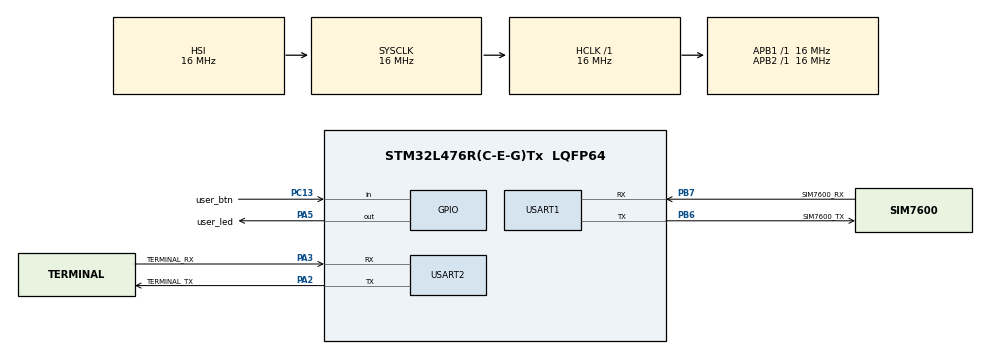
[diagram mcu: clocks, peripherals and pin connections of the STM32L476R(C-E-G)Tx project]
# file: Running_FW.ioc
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Mcu.Family=STM32L4
RCC.MSI_VALUE=4000000
RCC.PLLSourceVirtual=RCC_PLLSOURCE_HSI
PA14\ (JTCK-SWCLK).Mode=Serial_Wire
RCC.CortexFreq_Value=16000000
PC13.Signal=GPIO_Input
PB6.GPIO_Label=SIM7600_TX
PC13.GPIO_Label=user_btn
NVIC.USART2_IRQn=true\:0\:0\:false\:false\:true\:true\:true
RCC.SYSCLKSource=RCC_SYSCLKSOURCE_HSI
ProjectManager.StackSize=0x400
PA14\ (JTCK-SWCLK).Signal=SYS_JTCK-SWCLK
USART1.VirtualMode-Asynchronous=VM_ASYNC
PA3.Mode=Asynchronous
ProjectManager.TargetToolchain=STM32CubeIDE
RCC.HCLKFreq_Value=16000000
RCC.APB2TimFreq_Value=16000000
PB6.Signal=USART1_TX
PB6.Mode=Asynchronous
RCC.USBFreq_Value=64000000
RCC.AHBFreq_Value=16000000
RCC.PREFETCH_ENABLE=1
PA5.Signal=GPIO_Output
RCC.HSE_VALUE=8000000
board=NUCLEO-L476RG
USART2.VirtualMode-Asynchronous=VM_ASYNC
RCC.VCOOutputFreq_Value=160000000
RCC.APB2Freq_Value=16000000
RCC.ADCFreq_Value=64000000
PC13.GPIO_PuPd=GPIO_PULLUP
PB7.Signal=USART1_RX
Mcu.Name=STM32L476R(C-E-G)Tx
PA2.Signal=USART2_TX
PB7.GPIO_Label=SIM7600_RX
PA13\ (JTMS-SWDIO).Mode=Serial_Wire
RCC.SYSCLKFreq_VALUE=16000000
Mcu.Package=LQFP64
PA5.GPIO_Label=user_led
PA2.GPIO_Label=TERMINAL_TX
PB7.Mode=Asynchronous
ProjectManager.HeapSize=0x200
RCC.HSI_VALUE=16000000
PA5.GPIO_Speed=GPIO_SPEED_FREQ_VERY_HIGH
NVIC.PriorityGroup=NVIC_PRIORITYGROUP_4
RCC.PLLN=10
RCC.APB1TimFreq_Value=16000000
PA2.Mode=Asynchronous
PA13\ (JTMS-SWDIO).Signal=SYS_JTMS-SWDIO
NVIC.USART1_IRQn=true\:0\:0\:false\:false\:true\:true\:true
RCC.APB1Freq_Value=16000000
PA3.GPIO_Label=TERMINAL_RX
PA3.Signal=USART2_RX

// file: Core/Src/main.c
/* USER CODE BEGIN Header */
/**
  ******************************************************************************
  * @file           : main.c
  * @brief          : Main program body
  ******************************************************************************
  * @attention
  *
  * <h2><center>&copy; Copyright (c) 2021 STMicroelectronics.
  * All rights reserved.</center></h2>
  *
  * This software component is licensed by ST under BSD 3-Clause license,
  * the "License"; You may not use this file except in compliance with the
  * License. You may obtain a copy of the License at:
  *                        opensource.org/licenses/BSD-3-Clause
  *
  ******************************************************************************
  */
/* USER CODE END Header */
#include "main.h"
#include "usart.h"
#include "gpio.h"

/* USER CODE BEGIN Includes */
#include "string.h"
/* USER CODE END Includes */

void SystemClock_Config(void);

int main(void)
{
  /* USER CODE BEGIN 1 */
	SCB->VTOR = (uint32_t)0x08060000 ;

  /* USER CODE END 1 */

  /* MCU Configuration--------------------------------------------------------*/

  /* Reset of all peripherals, Initializes the Flash interface and the Systick. */
  HAL_Init();

  /* Configure the system clock */
  SystemClock_Config();

  /* Initialize all configured peripherals */
  MX_GPIO_Init();
  MX_USART2_UART_Init();
  MX_USART1_UART_Init();

  /* Infinite loop */
  while (1)
  {

    /* USER CODE BEGIN 3 */
	  char info[ 50 ] = "\nThis is Running Firmware" ;
	  HAL_UART_Transmit( &huart2, (uint8_t*)info, strlen( info ), 2000 ) ;
	  HAL_Delay( 1000 ) ;
  }
  /* USER CODE END 3 */
}

void SystemClock_Config(void)
{
  RCC_OscInitTypeDef RCC_OscInitStruct = {0};
  RCC_ClkInitTypeDef RCC_ClkInitStruct = {0};
  RCC_PeriphCLKInitTypeDef PeriphClkInit = {0};

  /** Initializes the RCC Oscillators according to the specified parameters
  * in the RCC_OscInitTypeDef structure.
  */
  RCC_OscInitStruct.OscillatorType = RCC_OSCILLATORTYPE_HSI;
  RCC_OscInitStruct.HSIState = RCC_HSI_ON;
  RCC_OscInitStruct.HSICalibrationValue = RCC_HSICALIBRATION_DEFAULT;
  RCC_OscInitStruct.PLL.PLLState = RCC_PLL_NONE;
  if (HAL_RCC_OscConfig(&RCC_OscInitStruct) != HAL_OK)
  {
    Error_Handler();
  }
  /** Initializes the CPU, AHB and APB buses clocks
  */
  RCC_ClkInitStruct.ClockType = RCC_CLOCKTYPE_HCLK|RCC_CLOCKTYPE_SYSCLK
                              |RCC_CLOCKTYPE_PCLK1|RCC_CLOCKTYPE_PCLK2;
  RCC_ClkInitStruct.SYSCLKSource = RCC_SYSCLKSOURCE_HSI;
  RCC_ClkInitStruct.AHBCLKDivider = RCC_SYSCLK_DIV1;
  RCC_ClkInitStruct.APB1CLKDivider = RCC_HCLK_DIV1;
  RCC_ClkInitStruct.APB2CLKDivider = RCC_HCLK_DIV1;

  if (HAL_RCC_ClockConfig(&RCC_ClkInitStruct, FLASH_LATENCY_0) != HAL_OK)
  {
    Error_Handler();
  }
  PeriphClkInit.PeriphClockSelection = RCC_PERIPHCLK_USART1|RCC_PERIPHCLK_USART2;
  PeriphClkInit.Usart1ClockSelection = RCC_USART1CLKSOURCE_PCLK2;
  PeriphClkInit.Usart2ClockSelection = RCC_USART2CLKSOURCE_PCLK1;
  if (HAL_RCCEx_PeriphCLKConfig(&PeriphClkInit) != HAL_OK)
  {
    Error_Handler();
  }
  /** Configure the main internal regulator output voltage
  */
  if (HAL_PWREx_ControlVoltageScaling(PWR_REGULATOR_VOLTAGE_SCALE1) != HAL_OK)
  {
    Error_Handler();
  }
}

void Error_Handler(void)
{
  __disable_irq();
  while (1)
  {
  }
}

/************************ (C) COPYRIGHT STMicroelectronics *****END OF FILE****/
